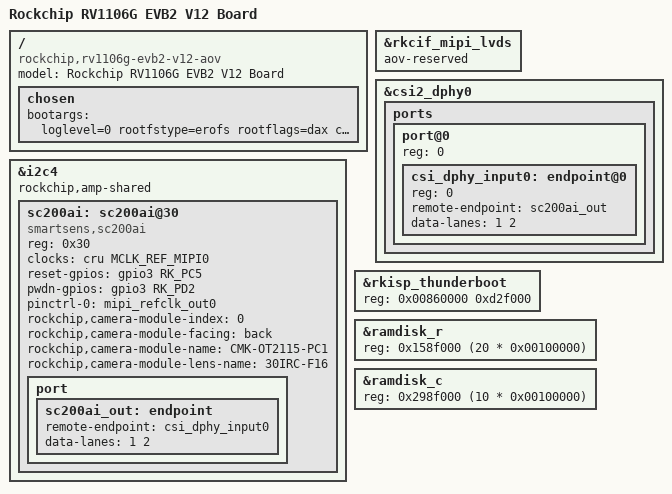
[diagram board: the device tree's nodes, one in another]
// SPDX-License-Identifier: (GPL-2.0+ OR MIT)
/*
 * Copyright (c) 2023 Rockchip Electronics Co., Ltd.
 */

/dts-v1/;

#include "rv1106g-evb2-v10.dts"

/ {
	model = "Rockchip RV1106G EVB2 V12 Board";
	compatible = "rockchip,rv1106g-evb2-v12-aov", "rockchip,rv1106";

	chosen {
		bootargs = "loglevel=0 rootfstype=erofs rootflags=dax console=ttyFIQ0 root=/dev/rd0 snd_soc_core.prealloc_buffer_size_kbytes=16 coherent_pool=0 driver_async_probe=dwmmc_rockchip";
	};

};

&rkcif_mipi_lvds {
	aov-reserved;
	status = "okay";
};

&csi2_dphy0 {
	status = "okay";

	ports {
		#address-cells = <1>;
		#size-cells = <0>;

		port@0 {
			reg = <0>;
			#address-cells = <1>;
			#size-cells = <0>;

			csi_dphy_input0: endpoint@0 {
				reg = <0>;
				remote-endpoint = <&sc200ai_out>;
				data-lanes = <1 2>;
			};
		};
	};
};

&i2c4 {
	rockchip,amp-shared;
	/delete-node/ sc3338@30;

	sc200ai: sc200ai@30 {
		compatible = "smartsens,sc200ai";
		status = "okay";
		reg = <0x30>;
		clocks = <&cru MCLK_REF_MIPI0>;
		clock-names = "xvclk";
		reset-gpios = <&gpio3 RK_PC5 GPIO_ACTIVE_HIGH>;
		pwdn-gpios = <&gpio3 RK_PD2 GPIO_ACTIVE_HIGH>;
		pinctrl-names = "default";
		pinctrl-0 = <&mipi_refclk_out0>;
		rockchip,camera-module-index = <0>;
		rockchip,camera-module-facing = "back";
		rockchip,camera-module-name = "CMK-OT2115-PC1";
		rockchip,camera-module-lens-name = "30IRC-F16";
		port {
			sc200ai_out: endpoint {
				remote-endpoint = <&csi_dphy_input0>;
				data-lanes = <1 2>;
			};
		};
	};
};

&rkisp_thunderboot {
	/* reg's offset MUST match with RTOS */
	/*
	 * vicap, capture raw10, ceil(w*10/8/256)*256*h *4(buf num)
	 * e.g. 2304x1296: 0xf30000
	 */
	reg = <0x00860000 0xd2f000>;
};

&ramdisk_r {
	reg = <0x158f000 (20 * 0x00100000)>;
};

&ramdisk_c {
	reg = <0x298f000 (10 * 0x00100000)>;
};
